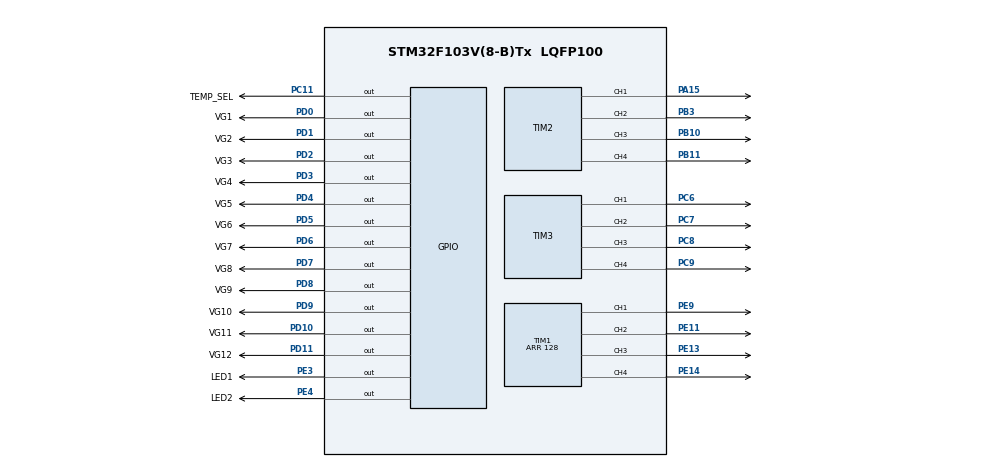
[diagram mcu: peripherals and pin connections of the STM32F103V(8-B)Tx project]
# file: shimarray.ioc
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Mcu.Family=STM32F1
Mcu.Name=STM32F103V(8-B)Tx
Mcu.Package=LQFP100
NVIC.PriorityGroup=NVIC_PRIORITYGROUP_4
OSC_IN.Mode=HSE-External-Oscillator
OSC_IN.Signal=RCC_OSC_IN
OSC_OUT.Mode=HSE-External-Oscillator
OSC_OUT.Signal=RCC_OSC_OUT
PA15.Signal=S_TIM2_CH1_ETR
PB10.Signal=S_TIM2_CH3
PB11.Signal=S_TIM2_CH4
PB3.Signal=S_TIM2_CH2
PC11.GPIO_Label=TEMP_SEL
PC11.Signal=GPIO_Output
PC6.Signal=S_TIM3_CH1
PC7.Signal=S_TIM3_CH2
PC8.Signal=S_TIM3_CH3
PC9.Signal=S_TIM3_CH4
PD0.GPIO_Label=VG1
PD0.Signal=GPIO_Output
PD1.GPIO_Label=VG2
PD1.Signal=GPIO_Output
PD10.GPIO_Label=VG11
PD10.Signal=GPIO_Output
PD11.GPIO_Label=VG12
PD11.Signal=GPIO_Output
PD2.GPIO_Label=VG3
PD2.Signal=GPIO_Output
PD3.GPIO_Label=VG4
PD3.Signal=GPIO_Output
PD4.GPIO_Label=VG5
PD4.Signal=GPIO_Output
PD5.GPIO_Label=VG6
PD5.Signal=GPIO_Output
PD6.GPIO_Label=VG7
PD6.Signal=GPIO_Output
PD7.GPIO_Label=VG8
PD7.Signal=GPIO_Output
PD8.GPIO_Label=VG9
PD8.Signal=GPIO_Output
PD9.GPIO_Label=VG10
PD9.Signal=GPIO_Output
PE11.Signal=S_TIM1_CH2
PE13.Signal=S_TIM1_CH3
PE14.Signal=S_TIM1_CH4
PE3.GPIO_Label=LED1
PE3.Signal=GPIO_Output
PE4.GPIO_Label=LED2
PE4.Signal=GPIO_Output
PE9.Signal=S_TIM1_CH1
ProjectManager.HeapSize=0x200
ProjectManager.StackSize=0x400
ProjectManager.TargetToolchain=STM32CubeIDE
RCC.APB1Freq_Value=8000000
RCC.APB2Freq_Value=8000000
RCC.HSE_VALUE=12000000
RCC.PLLSourceVirtual=RCC_PLLSOURCE_HSE
RCC.USBFreq_Value=24000000
SH.S_TIM1_CH1.0=TIM1_CH1,PWM Generation1 CH1
SH.S_TIM1_CH2.0=TIM1_CH2,PWM Generation2 CH2
SH.S_TIM1_CH3.0=TIM1_CH3,PWM Generation3 CH3
SH.S_TIM1_CH4.0=TIM1_CH4,PWM Generation4 CH4
SH.S_TIM2_CH1_ETR.0=TIM2_CH1,PWM Generation1 CH1
SH.S_TIM2_CH2.0=TIM2_CH2,PWM Generation2 CH2
SH.S_TIM2_CH3.0=TIM2_CH3,PWM Generation3 CH3
SH.S_TIM2_CH4.0=TIM2_CH4,PWM Generation4 CH4
SH.S_TIM3_CH1.0=TIM3_CH1,PWM Generation1 CH1
SH.S_TIM3_CH2.0=TIM3_CH2,PWM Generation2 CH2
SH.S_TIM3_CH3.0=TIM3_CH3,PWM Generation3 CH3
SH.S_TIM3_CH4.0=TIM3_CH4,PWM Generation4 CH4
TIM1.Channel-PWM\ Generation1\ CH1=TIM_CHANNEL_1
TIM1.Channel-PWM\ Generation2\ CH2=TIM_CHANNEL_2
TIM1.Channel-PWM\ Generation3\ CH3=TIM_CHANNEL_3
TIM1.Channel-PWM\ Generation4\ CH4=TIM_CHANNEL_4
TIM1.Period=128
TIM1.Pulse-PWM\ Generation1\ CH1=64
TIM2.Channel-PWM\ Generation1\ CH1=TIM_CHANNEL_1
TIM2.Channel-PWM\ Generation2\ CH2=TIM_CHANNEL_2
TIM2.Channel-PWM\ Generation3\ CH3=TIM_CHANNEL_3
TIM2.Channel-PWM\ Generation4\ CH4=TIM_CHANNEL_4
TIM3.Channel-PWM\ Generation1\ CH1=TIM_CHANNEL_1
TIM3.Channel-PWM\ Generation2\ CH2=TIM_CHANNEL_2
TIM3.Channel-PWM\ Generation3\ CH3=TIM_CHANNEL_3
TIM3.Channel-PWM\ Generation4\ CH4=TIM_CHANNEL_4
VP_SYS_VS_ND.Mode=No_Debug
VP_TIM1_VS_ClockSourceINT.Mode=Internal
VP_TIM2_VS_ClockSourceINT.Mode=Internal
VP_TIM3_VS_ClockSourceINT.Mode=Internal
board=custom

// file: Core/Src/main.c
/* USER CODE BEGIN Header */
/**
  ******************************************************************************
  * @file           : main.c
  * @brief          : Main program body
  ******************************************************************************
  * @attention
  *
  * Copyright (c) 2025 STMicroelectronics.
  * All rights reserved.
  *
  * This software is licensed under terms that can be found in the LICENSE file
  * in the root directory of this software component.
  * If no LICENSE file comes with this software, it is provided AS-IS.
  *
  ******************************************************************************
  */
/* USER CODE END Header */
#include "main.h"

TIM_HandleTypeDef htim1;
TIM_HandleTypeDef htim2;
TIM_HandleTypeDef htim3;

void SystemClock_Config(void);
static void MX_GPIO_Init(void);
static void MX_TIM1_Init(void);
static void MX_TIM2_Init(void);
static void MX_TIM3_Init(void);

int main(void)
{

  /* MCU Configuration--------------------------------------------------------*/

  /* Reset of all peripherals, Initializes the Flash interface and the Systick. */
  HAL_Init();

  /* Configure the system clock */
  SystemClock_Config();

  /* Initialize all configured peripherals */
  MX_GPIO_Init();
  MX_TIM1_Init();
  MX_TIM2_Init();
  MX_TIM3_Init();
  /* USER CODE BEGIN 2 */
  HAL_TIM_PWM_Start(&htim1, TIM_CHANNEL_2);
  uint8_t tval = 64;

  /* USER CODE END 2 */

  /* Infinite loop */
  while (1)
  {

    /* USER CODE BEGIN 3 */
	  HAL_GPIO_TogglePin(LED1_GPIO_Port, LED1_Pin);
	  HAL_GPIO_TogglePin(VG1_GPIO_Port, VG1_Pin);
//	  HAL_GPIO_TogglePin(TEMP_SEL_GPIO_Port, TEMP_SEL_Pin);
	  HAL_Delay(1000);
//	  tval = (tval + 8)%128;
//	  TIM1->CCR2 = tval;
  }
  /* USER CODE END 3 */
}

void SystemClock_Config(void)
{
  RCC_OscInitTypeDef RCC_OscInitStruct = {0};
  RCC_ClkInitTypeDef RCC_ClkInitStruct = {0};

  /** Initializes the RCC Oscillators according to the specified parameters
  * in the RCC_OscInitTypeDef structure.
  */
  RCC_OscInitStruct.OscillatorType = RCC_OSCILLATORTYPE_HSI;
  RCC_OscInitStruct.HSIState = RCC_HSI_ON;
  RCC_OscInitStruct.HSICalibrationValue = RCC_HSICALIBRATION_DEFAULT;
  RCC_OscInitStruct.PLL.PLLState = RCC_PLL_NONE;
  if (HAL_RCC_OscConfig(&RCC_OscInitStruct) != HAL_OK)
  {
    Error_Handler();
  }

  /** Initializes the CPU, AHB and APB buses clocks
  */
  RCC_ClkInitStruct.ClockType = RCC_CLOCKTYPE_HCLK|RCC_CLOCKTYPE_SYSCLK
                              |RCC_CLOCKTYPE_PCLK1|RCC_CLOCKTYPE_PCLK2;
  RCC_ClkInitStruct.SYSCLKSource = RCC_SYSCLKSOURCE_HSI;
  RCC_ClkInitStruct.AHBCLKDivider = RCC_SYSCLK_DIV1;
  RCC_ClkInitStruct.APB1CLKDivider = RCC_HCLK_DIV1;
  RCC_ClkInitStruct.APB2CLKDivider = RCC_HCLK_DIV1;

  if (HAL_RCC_ClockConfig(&RCC_ClkInitStruct, FLASH_LATENCY_0) != HAL_OK)
  {
    Error_Handler();
  }
}

static void MX_TIM1_Init(void)
{

  TIM_ClockConfigTypeDef sClockSourceConfig = {0};
  TIM_MasterConfigTypeDef sMasterConfig = {0};
  TIM_OC_InitTypeDef sConfigOC = {0};
  TIM_BreakDeadTimeConfigTypeDef sBreakDeadTimeConfig = {0};

  htim1.Instance = TIM1;
  htim1.Init.Prescaler = 0;
  htim1.Init.CounterMode = TIM_COUNTERMODE_UP;
  htim1.Init.Period = 128;
  htim1.Init.ClockDivision = TIM_CLOCKDIVISION_DIV1;
  htim1.Init.RepetitionCounter = 0;
  htim1.Init.AutoReloadPreload = TIM_AUTORELOAD_PRELOAD_DISABLE;
  if (HAL_TIM_Base_Init(&htim1) != HAL_OK)
  {
    Error_Handler();
  }
  sClockSourceConfig.ClockSource = TIM_CLOCKSOURCE_INTERNAL;
  if (HAL_TIM_ConfigClockSource(&htim1, &sClockSourceConfig) != HAL_OK)
  {
    Error_Handler();
  }
  if (HAL_TIM_PWM_Init(&htim1) != HAL_OK)
  {
    Error_Handler();
  }
  sMasterConfig.MasterOutputTrigger = TIM_TRGO_RESET;
  sMasterConfig.MasterSlaveMode = TIM_MASTERSLAVEMODE_DISABLE;
  if (HAL_TIMEx_MasterConfigSynchronization(&htim1, &sMasterConfig) != HAL_OK)
  {
    Error_Handler();
  }
  sConfigOC.OCMode = TIM_OCMODE_PWM1;
  sConfigOC.Pulse = 64;
  sConfigOC.OCPolarity = TIM_OCPOLARITY_HIGH;
  sConfigOC.OCNPolarity = TIM_OCNPOLARITY_HIGH;
  sConfigOC.OCFastMode = TIM_OCFAST_DISABLE;
  sConfigOC.OCIdleState = TIM_OCIDLESTATE_RESET;
  sConfigOC.OCNIdleState = TIM_OCNIDLESTATE_RESET;
  if (HAL_TIM_PWM_ConfigChannel(&htim1, &sConfigOC, TIM_CHANNEL_1) != HAL_OK)
  {
    Error_Handler();
  }
  sConfigOC.Pulse = 0;
  if (HAL_TIM_PWM_ConfigChannel(&htim1, &sConfigOC, TIM_CHANNEL_2) != HAL_OK)
  {
    Error_Handler();
  }
  if (HAL_TIM_PWM_ConfigChannel(&htim1, &sConfigOC, TIM_CHANNEL_3) != HAL_OK)
  {
    Error_Handler();
  }
  if (HAL_TIM_PWM_ConfigChannel(&htim1, &sConfigOC, TIM_CHANNEL_4) != HAL_OK)
  {
    Error_Handler();
  }
  sBreakDeadTimeConfig.OffStateRunMode = TIM_OSSR_DISABLE;
  sBreakDeadTimeConfig.OffStateIDLEMode = TIM_OSSI_DISABLE;
  sBreakDeadTimeConfig.LockLevel = TIM_LOCKLEVEL_OFF;
  sBreakDeadTimeConfig.DeadTime = 0;
  sBreakDeadTimeConfig.BreakState = TIM_BREAK_DISABLE;
  sBreakDeadTimeConfig.BreakPolarity = TIM_BREAKPOLARITY_HIGH;
  sBreakDeadTimeConfig.AutomaticOutput = TIM_AUTOMATICOUTPUT_DISABLE;
  if (HAL_TIMEx_ConfigBreakDeadTime(&htim1, &sBreakDeadTimeConfig) != HAL_OK)
  {
    Error_Handler();
  }
  HAL_TIM_MspPostInit(&htim1);

}

static void MX_TIM2_Init(void)
{

  TIM_ClockConfigTypeDef sClockSourceConfig = {0};
  TIM_MasterConfigTypeDef sMasterConfig = {0};
  TIM_OC_InitTypeDef sConfigOC = {0};

  htim2.Instance = TIM2;
  htim2.Init.Prescaler = 0;
  htim2.Init.CounterMode = TIM_COUNTERMODE_UP;
  htim2.Init.Period = 65535;
  htim2.Init.ClockDivision = TIM_CLOCKDIVISION_DIV1;
  htim2.Init.AutoReloadPreload = TIM_AUTORELOAD_PRELOAD_DISABLE;
  if (HAL_TIM_Base_Init(&htim2) != HAL_OK)
  {
    Error_Handler();
  }
  sClockSourceConfig.ClockSource = TIM_CLOCKSOURCE_INTERNAL;
  if (HAL_TIM_ConfigClockSource(&htim2, &sClockSourceConfig) != HAL_OK)
  {
    Error_Handler();
  }
  if (HAL_TIM_PWM_Init(&htim2) != HAL_OK)
  {
    Error_Handler();
  }
  sMasterConfig.MasterOutputTrigger = TIM_TRGO_RESET;
  sMasterConfig.MasterSlaveMode = TIM_MASTERSLAVEMODE_DISABLE;
  if (HAL_TIMEx_MasterConfigSynchronization(&htim2, &sMasterConfig) != HAL_OK)
  {
    Error_Handler();
  }
  sConfigOC.OCMode = TIM_OCMODE_PWM1;
  sConfigOC.Pulse = 0;
  sConfigOC.OCPolarity = TIM_OCPOLARITY_HIGH;
  sConfigOC.OCFastMode = TIM_OCFAST_DISABLE;
  if (HAL_TIM_PWM_ConfigChannel(&htim2, &sConfigOC, TIM_CHANNEL_1) != HAL_OK)
  {
    Error_Handler();
  }
  if (HAL_TIM_PWM_ConfigChannel(&htim2, &sConfigOC, TIM_CHANNEL_2) != HAL_OK)
  {
    Error_Handler();
  }
  if (HAL_TIM_PWM_ConfigChannel(&htim2, &sConfigOC, TIM_CHANNEL_3) != HAL_OK)
  {
    Error_Handler();
  }
  if (HAL_TIM_PWM_ConfigChannel(&htim2, &sConfigOC, TIM_CHANNEL_4) != HAL_OK)
  {
    Error_Handler();
  }
  HAL_TIM_MspPostInit(&htim2);

}

static void MX_TIM3_Init(void)
{

  TIM_ClockConfigTypeDef sClockSourceConfig = {0};
  TIM_MasterConfigTypeDef sMasterConfig = {0};
  TIM_OC_InitTypeDef sConfigOC = {0};

  htim3.Instance = TIM3;
  htim3.Init.Prescaler = 0;
  htim3.Init.CounterMode = TIM_COUNTERMODE_UP;
  htim3.Init.Period = 65535;
  htim3.Init.ClockDivision = TIM_CLOCKDIVISION_DIV1;
  htim3.Init.AutoReloadPreload = TIM_AUTORELOAD_PRELOAD_DISABLE;
  if (HAL_TIM_Base_Init(&htim3) != HAL_OK)
  {
    Error_Handler();
  }
  sClockSourceConfig.ClockSource = TIM_CLOCKSOURCE_INTERNAL;
  if (HAL_TIM_ConfigClockSource(&htim3, &sClockSourceConfig) != HAL_OK)
  {
    Error_Handler();
  }
  if (HAL_TIM_PWM_Init(&htim3) != HAL_OK)
  {
    Error_Handler();
  }
  sMasterConfig.MasterOutputTrigger = TIM_TRGO_RESET;
  sMasterConfig.MasterSlaveMode = TIM_MASTERSLAVEMODE_DISABLE;
  if (HAL_TIMEx_MasterConfigSynchronization(&htim3, &sMasterConfig) != HAL_OK)
  {
    Error_Handler();
  }
  sConfigOC.OCMode = TIM_OCMODE_PWM1;
  sConfigOC.Pulse = 0;
  sConfigOC.OCPolarity = TIM_OCPOLARITY_HIGH;
  sConfigOC.OCFastMode = TIM_OCFAST_DISABLE;
  if (HAL_TIM_PWM_ConfigChannel(&htim3, &sConfigOC, TIM_CHANNEL_1) != HAL_OK)
  {
    Error_Handler();
  }
  if (HAL_TIM_PWM_ConfigChannel(&htim3, &sConfigOC, TIM_CHANNEL_2) != HAL_OK)
  {
    Error_Handler();
  }
  if (HAL_TIM_PWM_ConfigChannel(&htim3, &sConfigOC, TIM_CHANNEL_3) != HAL_OK)
  {
    Error_Handler();
  }
  if (HAL_TIM_PWM_ConfigChannel(&htim3, &sConfigOC, TIM_CHANNEL_4) != HAL_OK)
  {
    Error_Handler();
  }
  HAL_TIM_MspPostInit(&htim3);

}

static void MX_GPIO_Init(void)
{
  GPIO_InitTypeDef GPIO_InitStruct = {0};

  /* GPIO Ports Clock Enable */
  __HAL_RCC_GPIOE_CLK_ENABLE();
  __HAL_RCC_GPIOB_CLK_ENABLE();
  __HAL_RCC_GPIOD_CLK_ENABLE();
  __HAL_RCC_GPIOC_CLK_ENABLE();
  __HAL_RCC_GPIOA_CLK_ENABLE();

  /*Configure GPIO pin Output Level */
  HAL_GPIO_WritePin(GPIOE, LED1_Pin|LED2_Pin, GPIO_PIN_RESET);

  /*Configure GPIO pin Output Level */
  HAL_GPIO_WritePin(GPIOD, VG9_Pin|VG10_Pin|VG11_Pin|VG12_Pin
                          |VG1_Pin|VG2_Pin|VG3_Pin|VG4_Pin
                          |VG5_Pin|VG6_Pin|VG7_Pin|VG8_Pin, GPIO_PIN_RESET);

  /*Configure GPIO pin Output Level */
  HAL_GPIO_WritePin(TEMP_SEL_GPIO_Port, TEMP_SEL_Pin, GPIO_PIN_RESET);

  /*Configure GPIO pins : LED1_Pin LED2_Pin */
  GPIO_InitStruct.Pin = LED1_Pin|LED2_Pin;
  GPIO_InitStruct.Mode = GPIO_MODE_OUTPUT_PP;
  GPIO_InitStruct.Pull = GPIO_NOPULL;
  GPIO_InitStruct.Speed = GPIO_SPEED_FREQ_LOW;
  HAL_GPIO_Init(GPIOE, &GPIO_InitStruct);

  /*Configure GPIO pins : VG9_Pin VG10_Pin VG11_Pin VG12_Pin
                           VG1_Pin VG2_Pin VG3_Pin VG4_Pin
                           VG5_Pin VG6_Pin VG7_Pin VG8_Pin */
  GPIO_InitStruct.Pin = VG9_Pin|VG10_Pin|VG11_Pin|VG12_Pin
                          |VG1_Pin|VG2_Pin|VG3_Pin|VG4_Pin
                          |VG5_Pin|VG6_Pin|VG7_Pin|VG8_Pin;
  GPIO_InitStruct.Mode = GPIO_MODE_OUTPUT_PP;
  GPIO_InitStruct.Pull = GPIO_NOPULL;
  GPIO_InitStruct.Speed = GPIO_SPEED_FREQ_LOW;
  HAL_GPIO_Init(GPIOD, &GPIO_InitStruct);

  /*Configure GPIO pin : TEMP_SEL_Pin */
  GPIO_InitStruct.Pin = TEMP_SEL_Pin;
  GPIO_InitStruct.Mode = GPIO_MODE_OUTPUT_PP;
  GPIO_InitStruct.Pull = GPIO_NOPULL;
  GPIO_InitStruct.Speed = GPIO_SPEED_FREQ_LOW;
  HAL_GPIO_Init(TEMP_SEL_GPIO_Port, &GPIO_InitStruct);

}

void Error_Handler(void)
{
  __disable_irq();
  while (1)
  {
  }
}
